AUTOSAR XML (schema 4.0)
package /ADAS_Components
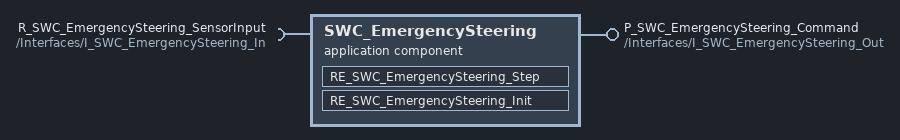
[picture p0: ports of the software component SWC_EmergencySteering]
  application sw component type SWC_EmergencySteering  # AUTOSAR Application SWC SWC_EmergencySteering for ADAS control sub-system
    provide port P_SWC_EmergencySteering_Command: provided-interface=/Interfaces/I_SWC_EmergencySteering_Out
    require port R_SWC_EmergencySteering_SensorInput: required-interface=/Interfaces/I_SWC_EmergencySteering_In
    behavior SWC_EmergencySteering_Behavior
      runnable RE_SWC_EmergencySteering_Step: symbol=SWC_EmergencySteering_Step
      runnable RE_SWC_EmergencySteering_Init: symbol=SWC_EmergencySteering_Init
  sender receiver interface I_SWC_EmergencySteering_Out  # Sender Receiver Interface for SWC_EmergencySteering outputs
    data DE_SWC_EmergencySteering_Signal: type=/AUTOSAR/Platform/uint32
  sender receiver interface I_SWC_EmergencySteering_In  # Sender Receiver Interface for SWC_EmergencySteering inputs
    data DE_SWC_EmergencySteering_RawData: type=/AUTOSAR/Platform/uint16
